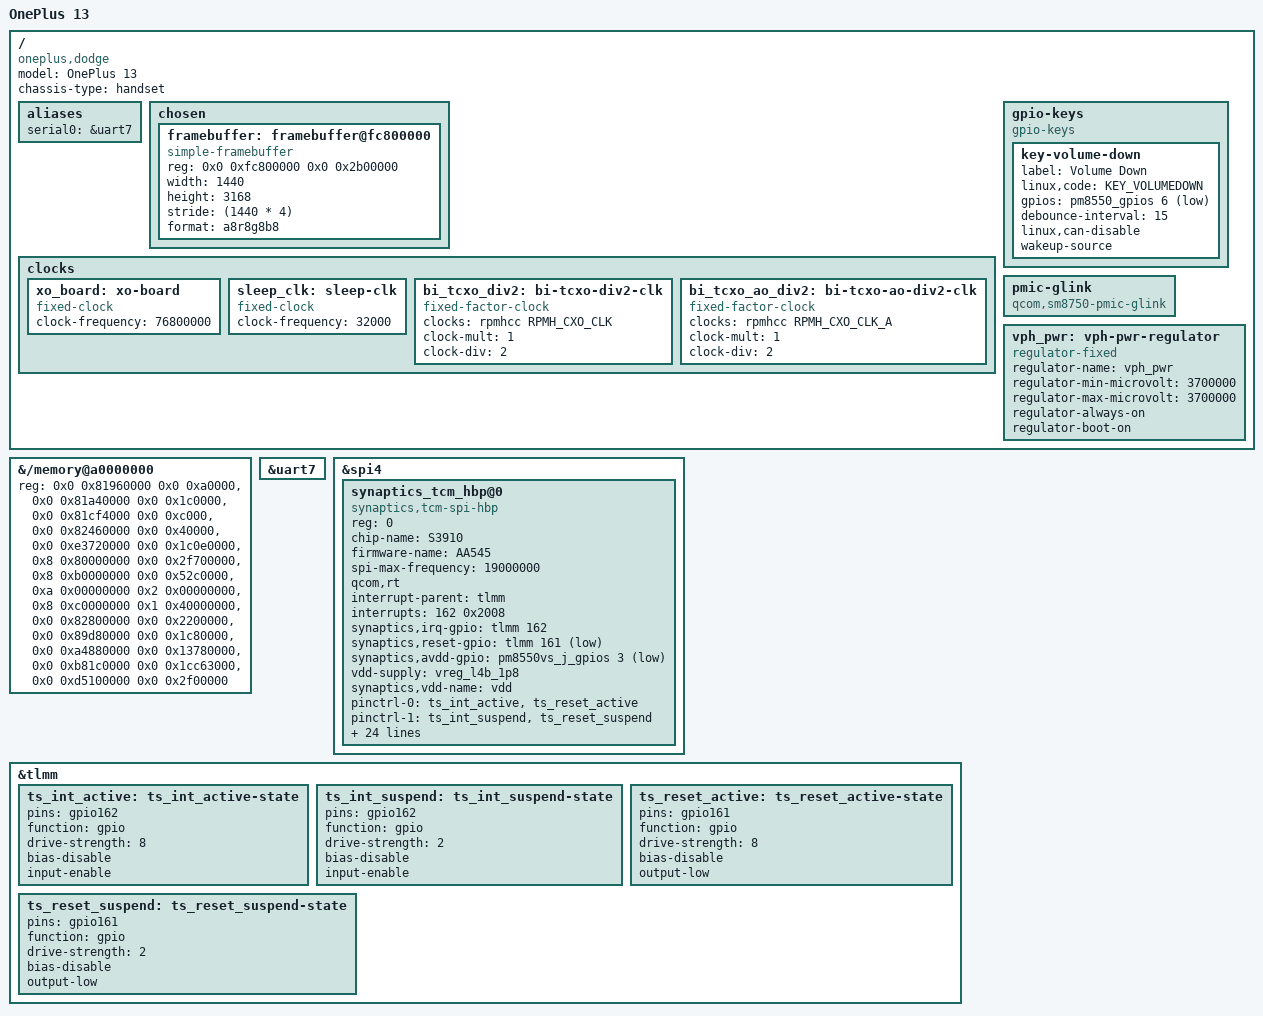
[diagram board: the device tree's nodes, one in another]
// SPDX-License-Identifier: BSD-3-Clause
/*
 * OnePlus 13 (dodge / PJZ110 / OP5D0DL1) device tree.
 *
 * Based on sm8750-mainline OnePlus-13-WIP, OnePlusOSS dodge 23821 overlays,
 * and verified root dump from the actual device.
 */

/dts-v1/;

#include <dt-bindings/gpio/gpio.h>
#include <dt-bindings/input/input.h>
#include "sm8750.dtsi"
#include "pm8010.dtsi"
#include "pm8550.dtsi"
#define PMK8550VE_SID 8
#include "pm8550ve.dtsi"
#include "pmih0108.dtsi"
#include "pmk8550.dtsi"
#include "pmr735d_a.dtsi"
#include "sm8750-pmics.dtsi"

/ {
	model = "OnePlus 13";
	compatible = "oneplus,dodge", "qcom,sm8750";
	chassis-type = "handset";

	aliases {
		serial0 = &uart7;
	};

	chosen {
		#address-cells = <2>;
		#size-cells = <2>;
		ranges;

		framebuffer: framebuffer@fc800000 {
			compatible = "simple-framebuffer";
			reg = <0x0 0xfc800000 0x0 0x2b00000>;
			width = <1440>;
			height = <3168>;
			stride = <(1440 * 4)>;
			format = "a8r8g8b8";
		};
	};

	clocks {
		xo_board: xo-board {
			compatible = "fixed-clock";
			clock-frequency = <76800000>;
			#clock-cells = <0>;
		};

		sleep_clk: sleep-clk {
			compatible = "fixed-clock";
			clock-frequency = <32000>;
			#clock-cells = <0>;
		};

		bi_tcxo_div2: bi-tcxo-div2-clk {
			compatible = "fixed-factor-clock";
			#clock-cells = <0>;
			clocks = <&rpmhcc RPMH_CXO_CLK>;
			clock-mult = <1>;
			clock-div = <2>;
		};

		bi_tcxo_ao_div2: bi-tcxo-ao-div2-clk {
			compatible = "fixed-factor-clock";
			#clock-cells = <0>;
			clocks = <&rpmhcc RPMH_CXO_CLK_A>;
			clock-mult = <1>;
			clock-div = <2>;
		};
	};

	gpio-keys {
		compatible = "gpio-keys";

		key-volume-down {
			label = "Volume Down";
			linux,code = <KEY_VOLUMEDOWN>;
			gpios = <&pm8550_gpios 6 GPIO_ACTIVE_LOW>;
			debounce-interval = <15>;
			linux,can-disable;
			wakeup-source;
		};
	};

	pmic-glink {
		compatible = "qcom,sm8750-pmic-glink", "qcom,pmic-glink";
		#address-cells = <1>;
		#size-cells = <0>;
	};

	vph_pwr: vph-pwr-regulator {
		compatible = "regulator-fixed";
		regulator-name = "vph_pwr";
		regulator-min-microvolt = <3700000>;
		regulator-max-microvolt = <3700000>;
		regulator-always-on;
		regulator-boot-on;
	};
};

&{/memory@a0000000} {
	device_type = "memory";
	reg = <0x0 0x81960000 0x0 0xa0000>,
	      <0x0 0x81a40000 0x0 0x1c0000>,
	      <0x0 0x81cf4000 0x0 0xc000>,
	      <0x0 0x82460000 0x0 0x40000>,
	      <0x0 0xe3720000 0x0 0x1c0e0000>,
	      <0x8 0x80000000 0x0 0x2f700000>,
	      <0x8 0xb0000000 0x0 0x52c0000>,
	      <0xa 0x00000000 0x2 0x00000000>,
	      <0x8 0xc0000000 0x1 0x40000000>,
	      <0x0 0x82800000 0x0 0x2200000>,
	      <0x0 0x89d80000 0x0 0x1c80000>,
	      <0x0 0xa4880000 0x0 0x13780000>,
	      <0x0 0xb81c0000 0x0 0x1cc63000>,
	      <0x0 0xd5100000 0x0 0x2f00000>;
};

&uart7 {
	status = "okay";
};

/*
 * Touchscreen support taken from the actual dodge/23821 OnePlusOSS overlay,
 * skb8/sm8750 dtbo notes, and the pmos/NixOS working DTS using the same
 * Synaptics TCM HBP binding.
 */
&spi4 {
	status = "okay";

	synaptics_tcm_hbp@0 {
		compatible = "synaptics,tcm-spi-hbp";
		reg = <0>;
		chip-name = "S3910";
		firmware-name = "AA545";
		spi-max-frequency = <19000000>;
		qcom,rt;

		interrupt-parent = <&tlmm>;
		interrupts = <162 0x2008>;
		synaptics,irq-gpio = <&tlmm 162 0x2008>;
		synaptics,reset-gpio = <&tlmm 161 GPIO_ACTIVE_LOW>;
		synaptics,avdd-gpio = <&pm8550vs_j_gpios 3 GPIO_ACTIVE_LOW>;
		vdd-supply = <&vreg_l4b_1p8>;
		synaptics,vdd-name = "vdd";

		pinctrl-names = "ts_spi_active", "ts_spi_suspend";
		pinctrl-0 = <&ts_int_active &ts_reset_active>;
		pinctrl-1 = <&ts_int_suspend &ts_reset_suspend>;

		touchpanel,panel-coords = <23040 50688>;
		touchpanel,tx-rx-num = <17 38>;
		panel_type = <10 3 3 3>;
		platform_support_project = <23821 23893 23894 23895>;
		platform_support_project_dir = <23821 23821 23821 23821>;
		platform_support_project_commandline =
			"mdss_dsi_panel_AA569_P_3_A0019_dsc_cmd_2nd",
			"mdss_dsi_panel_AA545_P_3_A0005_dsc_cmd",
			"mdss_dsi_panel_BF262_P_3_A0021_dsc_cmd",
			"mdss_dsi_panel_AA569_P_3_A0019_dsc_cmd";

		synaptics,power-on-state = <1>;
		synaptics,power-delay-ms = <200>;
		synaptics,irq-on-state = <0>;
		synaptics,reset-on-state = <0>;
		synaptics,reset-active-ms = <10>;
		synaptics,reset-delay-ms = <80>;
		synaptics,spi-mode = <0>;
		synaptics,spi-byte-delay-us = <0>;
		synaptics,spi-block-delay-us = <0>;

		touchpanel,panel-coords = <23040 50688>;
		tp_data_record_support;
		stats_upload_support;
		fingerprint_not_report_in_suspend;
	};
};

&tlmm {
	ts_int_active: ts_int_active-state {
		pins = "gpio162";
		function = "gpio";
		drive-strength = <8>;
		bias-disable;
		input-enable;
	};

	ts_int_suspend: ts_int_suspend-state {
		pins = "gpio162";
		function = "gpio";
		drive-strength = <2>;
		bias-disable;
		input-enable;
	};

	ts_reset_active: ts_reset_active-state {
		pins = "gpio161";
		function = "gpio";
		drive-strength = <8>;
		bias-disable;
		output-low;
	};

	ts_reset_suspend: ts_reset_suspend-state {
		pins = "gpio161";
		function = "gpio";
		drive-strength = <2>;
		bias-disable;
		output-low;
	};
};
